# PADCFG_CTRL_PADCFG_CTRL_CFG0_04080000h register map
Vendor: Texas Instruments
Peripheral module from a debugger description file (folder am62L).
Registers are 32-bit, access per field, reset 0x8214007 unless marked. A register's access mark holds for its fields unless they carry their own. Offsets are as the file gives them; lines under a group give offsets from that group; [hi:lo] are bit positions; {n}, {i} and the like mark numbered series; 'fields as' and 'values as' point back to an identical list; <NAME> marks a mode.

## PADCFG_CTRL_CFG0 (part 1 of 2)
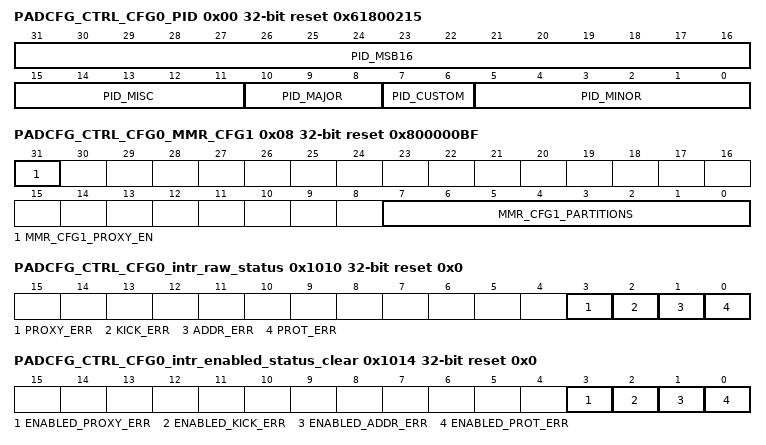
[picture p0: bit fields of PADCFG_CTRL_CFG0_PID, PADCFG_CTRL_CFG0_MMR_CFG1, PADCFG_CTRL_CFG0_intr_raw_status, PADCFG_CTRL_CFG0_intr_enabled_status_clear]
0x00 PADCFG_CTRL_CFG0_PID ro reset 0x61800215
  [31:16] PID_MSB16 — Reset Source: mod_g_rst_n
  [15:11] PID_MISC — Reset Source: mod_g_rst_n
  [10:8] PID_MAJOR — Reset Source: mod_g_rst_n
  [7:6] PID_CUSTOM — Reset Source: mod_g_rst_n
  [5:0] PID_MINOR — Reset Source: mod_g_rst_n
0x08 PADCFG_CTRL_CFG0_MMR_CFG1 ro reset 0x800000BF — Indicates the MMR configuration
  [31] MMR_CFG1_PROXY_EN — Proxy addressing enabled Reset Source: mod_por_rst_n
  [7:0] MMR_CFG1_PARTITIONS — Indicates present partitions Reset Source: mod_por_rst_n
0x1010 PADCFG_CTRL_CFG0_intr_raw_status access not given reset 0x0
  [3] PROXY_ERR — Proxy0 access violation error. Raw status is read. Write a 1 to set the status. Writing a 0 has no effect. Reset Source: mod_g_rst_n (access R/W1TS)
  [2] KICK_ERR — Kick access violation error. Raw status is read. Write a 1 to set the status. Writing a 0 has no effect. Reset Source: mod_g_rst_n (access R/W1TS)
  [1] ADDR_ERR — Addressing violation error. Raw status is read. Write a 1 to set the status. Writing a 0 has no effect. Reset Source: mod_g_rst_n (access R/W1TS)
  [0] PROT_ERR — Protection violation error. Raw status is read. Write a 1 to set the status. Writing a 0 has no effect. Reset Source: mod_g_rst_n (access R/W1TS)
0x1014 PADCFG_CTRL_CFG0_intr_enabled_status_clear access not given reset 0x0
  [3] ENABLED_PROXY_ERR — Proxy0 access violation error. Enabled status is read. Write a 1 to clear the status. Writing a 0 has no effect. Reset Source: mod_g_rst_n (access R/W1TC)
  [2] ENABLED_KICK_ERR — Kick access violation error. Enabled status is read. Write a 1 to clear the status. Writing a 0 has no effect. Reset Source: mod_g_rst_n (access R/W1TC)
  [1] ENABLED_ADDR_ERR — Addressing violation error. Enabled status is read. Write a 1 to clear the status. Writing a 0 has no effect. Reset Source: mod_g_rst_n (access R/W1TC)
  [0] ENABLED_PROT_ERR — Protection violation error. Enabled status is read. Write a 1 to clear the status. Writing a 0 has no effect. Reset Source: mod_g_rst_n (access R/W1TC)
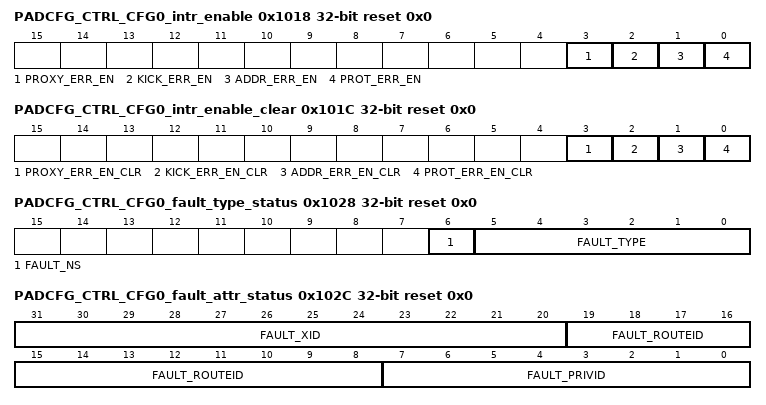
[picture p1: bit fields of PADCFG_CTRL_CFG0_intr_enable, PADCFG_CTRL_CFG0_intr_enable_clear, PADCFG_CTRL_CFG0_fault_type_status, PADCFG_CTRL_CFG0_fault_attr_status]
0x1018 PADCFG_CTRL_CFG0_intr_enable access not given reset 0x0
  [3] PROXY_ERR_EN — Proxy0 access violation error enable. Write a 1 to set the enable. Writing a 0 has no effect. Reset Source: mod_g_rst_n (access R/W1TS)
  [2] KICK_ERR_EN — Kick access violation error enable. Write a 1 to set the enable. Writing a 0 has no effect. Reset Source: mod_g_rst_n (access R/W1TS)
  [1] ADDR_ERR_EN — Addressing violation error enable. Write a 1 to set the enable. Writing a 0 has no effect. Reset Source: mod_g_rst_n (access R/W1TS)
  [0] PROT_ERR_EN — Protection violation error enable. Write a 1 to set the enable. Writing a 0 has no effect. Reset Source: mod_g_rst_n (access R/W1TS)
0x101C PADCFG_CTRL_CFG0_intr_enable_clear access not given reset 0x0
  [3] PROXY_ERR_EN_CLR — Proxy0 access violation error enable clear. Write a 1 to clear the enable. Writing a 0 has no effect. Reset Source: mod_g_rst_n (access R/W1TC)
  [2] KICK_ERR_EN_CLR — Kick access violation error enable clear. Write a 1 to clear the enable. Writing a 0 has no effect. Reset Source: mod_g_rst_n (access R/W1TC)
  [1] ADDR_ERR_EN_CLR — Addressing violation error enable clear. Write a 1 to clear the enable. Writing a 0 has no effect. Reset Source: mod_g_rst_n (access R/W1TC)
  [0] PROT_ERR_EN_CLR — Protection violation error enable clear. Write a 1 to clear the enable. Writing a 0 has no effect. Reset Source: mod_g_rst_n (access R/W1TC)
0x1020 PADCFG_CTRL_CFG0_eoi rw reset 0x0
  [7:0] EOI_VECTOR — EOI vector value. Write this with interrupt distribution value in the chip. Reset Source: mod_g_rst_n
0x1024 PADCFG_CTRL_CFG0_fault_address ro reset 0x0
  [31:0] FAULT_ADDR — Fault Address. Reset Source: mod_g_rst_n
0x1028 PADCFG_CTRL_CFG0_fault_type_status ro reset 0x0
  [6] FAULT_NS — Non-secure access. Reset Source: mod_g_rst_n
  [5:0] FAULT_TYPE — Fault Type 10_0000 = Supervisor read fault - priv = 1 dir = 1 dtype != 1 01_0000 = Supervisor write fault - priv = 1 dir = 0 00_1000 = Supervisor execute fault - priv = 1 dir = 1 dtype = 1 00_0100 = User read fault - priv = 0 dir = 1 dtype = 1 00_0010 = User write fault - priv = 0 dir = 0 00_0001 = User execute fault - priv = 0 dir = 1 dtype = 1 00_0000 = No fault Reset Source: mod_g_rst_n
0x102C PADCFG_CTRL_CFG0_fault_attr_status ro reset 0x0
  [31:20] FAULT_XID — XID. Reset Source: mod_g_rst_n
  [19:8] FAULT_ROUTEID — Route ID. Reset Source: mod_g_rst_n
  [7:0] FAULT_PRIVID — Privilege ID. Reset Source: mod_g_rst_n
0x1030 PADCFG_CTRL_CFG0_fault_clear wo reset 0x0
  [0] FAULT_CLR — Fault clear. Writing a 1 clears the current fault. Writing a 0 has no effect. Reset Source: mod_g_rst_n
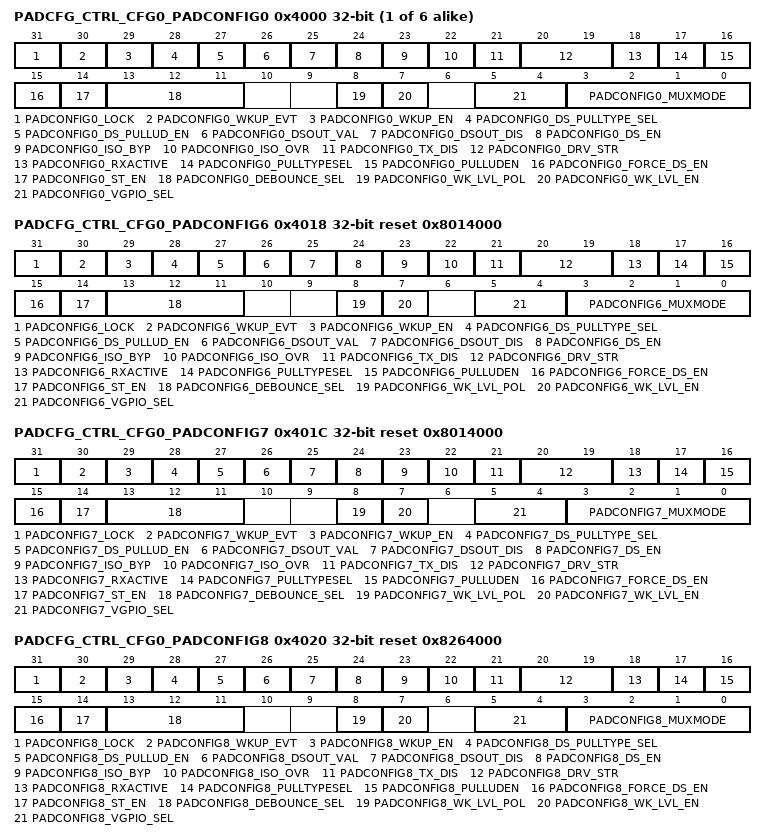
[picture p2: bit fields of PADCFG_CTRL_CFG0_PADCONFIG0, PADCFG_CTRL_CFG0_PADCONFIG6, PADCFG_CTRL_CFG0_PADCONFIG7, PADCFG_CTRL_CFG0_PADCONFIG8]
{0x4000+4i} PADCFG_CTRL_CFG0_PADCONFIG{i} (i=0..5) — Register to control pin configuration and muxing
  [31] PADCONFIG{i}_LOCK rw — Lock 0 - Padconfig register is unlocked 1 - Padconfig register is locked from further writes Reset Source: mod_por_rst_n
  [30] PADCONFIG{i}_WKUP_EVT ro — Wakeup event status 0 - No wake event on pin 1 - Wake event occurred on pin Reset Source: mod_por_rst_n
  [29] PADCONFIG{i}_WKUP_EN rw — Wakeup enable 0 - Wakeup operation disabled 1 - Wakeup operation enabled Reset Source: mod_por_rst_n
  [28] PADCONFIG{i}_DS_PULLTYPE_SEL rw — Deep Sleep pull-up/down selection 0 - Offmode pulldown selected 1 - Offmode pullup selected Reset Source: mod_por_rst_n
  [27] PADCONFIG{i}_DS_PULLUD_EN rw — Deep Sleep pull-up/down enable (active low) 0 - Pullup / pulldown is enabled 1 - Pullup / pulldown is disabled Reset Source: mod_por_rst_n
  [26] PADCONFIG{i}_DSOUT_VAL rw — Deep Sleep output value 0 - Output value is 0 1 - Output value is 1 Reset Source: mod_por_rst_n
  [25] PADCONFIG{i}_DSOUT_DIS rw — Deep Sleep output disable 0 - Output enabled 1 - Output disabled Reset Source: mod_por_rst_n
  [24] PADCONFIG{i}_DS_EN rw — Deep Sleep override control 0 - IO keeps its previous state when Deep Sleep mode is active 1 - IO state is forced to OFF mode value when Deep Sleep mode is active Reset Source: mod_por_rst_n
  [23] PADCONFIG{i}_ISO_BYP rw — Isolation Bypass0 - IO isolation is preserved1 - IO isolation is bypassed Reset Source: mod_por_rst_n
  [22] PADCONFIG{i}_ISO_OVR rw — Isolation Override0 - IO isolation is preserved1 - IO isolation is overridden Reset Source: mod_por_rst_n
  [21] PADCONFIG{i}_TX_DIS rw — Driver Disable0 - Driver is enabled1 - Driver is disabled Reset Source: mod_por_rst_n
  [20:19] PADCONFIG{i}_DRV_STR rw — Drive Strength Control for dual volatge IOs. Selects the drive strength value for LVCMOS pins. For 1.8V only IO, bitundefined maps to Slew Control pin. Reset Source: mod_por_rst_n
  [18] PADCONFIG{i}_RXACTIVE rw — Input enable for the Pad0 - Receiver disabled1 - Receiver enabled Reset Source: mod_por_rst_n
  [17] PADCONFIG{i}_PULLTYPESEL rw — Pad Pullup / Pulldown type selection0 - Pulldown selected1 - Pullup selected Reset Source: mod_por_rst_n
  [16] PADCONFIG{i}_PULLUDEN rw — Pad Pullup / Pulldown enable. This is an active low signal.0 - Pullup / Pulldown enabled1 - Pullup / Pulldown disabled Reset Source: mod_por_rst_n
  [15] PADCONFIG{i}_FORCE_DS_EN rw — Enable pad Deep Sleep controls by overriding WKUP DM gating0 - Deep Sleep pad controls are gated by the WKUP DM1 - Activate Deep Sleep pad controls (override WKUP DM gating logic) Reset Source: mod_por_rst_n
  [14] PADCONFIG{i}_ST_EN rw — Receiver Schmitt Trigger enable 0 - Schmitt trigger input disabled 1 - Schmitt trigger input enabled Reset Source: mod_por_rst_n
  [13:11] PADCONFIG{i}_DEBOUNCE_SEL rw — Selects the debouce period for the pad. Reset Source: mod_por_rst_n
  [8] PADCONFIG{i}_WK_LVL_POL rw — Level Sensitive Wakeup PolarityThis bit is not relevant unless wk_lvl_en is set to 1'b1.0 - Low. A low (0) value on the pin causes a wakeup1 - High. A high (1) value on the pin causes a wakeup Reset Source: mod_por_rst_n
  [7] PADCONFIG{i}_WK_LVL_EN rw — Level Sensitive Wakeup Enable0 - Disabled. Wakeup is triggered by change of the pin input value1 - Enabled. Wakeup is triggered when the pin matches the value specified by wk_lvl_pol. The chosen polarity must be maintained. (e.g. until wakeup completion is confirmed) Reset Source: mod_por_rst_n
  [5:4] PADCONFIG{i}_VGPIO_SEL rw — Virtual MAIN_GPIO instance select.These bits select which instance of GPIO is used for this I/O pad. This allows protection between two different Processor virtual worlds. These bits have no effect if GPIO mode (muxmode=7) is not selected for the PAD. Refer Pinmux to identify if a pin supports virtual GPIO function or not.Field values (others are reserved):2'b00 - Implement GPIO in GPIO_0 instance2'b01 - Implement GPIO in GPIO_2 instance Reset Source: mod_por_rst_n
  [3:0] PADCONFIG{i}_MUXMODE rw — Pad functional signal mux selectionField values (others are reserved):4'b0000 - Mux Mode 04'b0001 - Mux Mode 14'b0010 - Mux Mode 24'b0011 - Mux Mode 34'b0100 - Mux Mode 44'b0101 - Mux Mode 54'b0110 - Mux Mode 64'b0111 - Mux Mode 74'b1000 - Mux Mode 84'b1001 - Mux Mode 94'b1010 - Mux Mode 104'b1011 - Mux Mode 114'b1100 - Mux Mode 124'b1101 - Mux Mode 134'b1110 - Mux Mode 144'b1111 - Mux Mode 15 Reset Source: mod_por_rst_n
0x4018 PADCFG_CTRL_CFG0_PADCONFIG6 reset 0x8014000 — Register to control pin configuration and muxing
  [31] PADCONFIG6_LOCK rw — Lock 0 - Padconfig register is unlocked 1 - Padconfig register is locked from further writes Reset Source: mod_por_rst_n
  [30] PADCONFIG6_WKUP_EVT ro — Wakeup event status 0 - No wake event on pin 1 - Wake event occurred on pin Reset Source: mod_por_rst_n
  [29] PADCONFIG6_WKUP_EN rw — Wakeup enable 0 - Wakeup operation disabled 1 - Wakeup operation enabled Reset Source: mod_por_rst_n
  [28] PADCONFIG6_DS_PULLTYPE_SEL rw — Deep Sleep pull-up/down selection 0 - Offmode pulldown selected 1 - Offmode pullup selected Reset Source: mod_por_rst_n
  [27] PADCONFIG6_DS_PULLUD_EN rw — Deep Sleep pull-up/down enable (active low) 0 - Pullup / pulldown is enabled 1 - Pullup / pulldown is disabled Reset Source: mod_por_rst_n
  [26] PADCONFIG6_DSOUT_VAL rw — Deep Sleep output value 0 - Output value is 0 1 - Output value is 1 Reset Source: mod_por_rst_n
  [25] PADCONFIG6_DSOUT_DIS rw — Deep Sleep output disable 0 - Output enabled 1 - Output disabled Reset Source: mod_por_rst_n
  [24] PADCONFIG6_DS_EN rw — Deep Sleep override control 0 - IO keeps its previous state when Deep Sleep mode is active 1 - IO state is forced to OFF mode value when Deep Sleep mode is active Reset Source: mod_por_rst_n
  [23] PADCONFIG6_ISO_BYP rw — Isolation Bypass0 - IO isolation is preserved1 - IO isolation is bypassed Reset Source: mod_por_rst_n
  [22] PADCONFIG6_ISO_OVR rw — Isolation Override0 - IO isolation is preserved1 - IO isolation is overridden Reset Source: mod_por_rst_n
  [21] PADCONFIG6_TX_DIS rw — Driver Disable0 - Driver is enabled1 - Driver is disabled Reset Source: mod_por_rst_n
  [20:19] PADCONFIG6_DRV_STR rw — Drive Strength Control for dual volatge IOs. Selects the drive strength value for LVCMOS pins. For 1.8V only IO, bitundefined maps to Slew Control pin. Reset Source: mod_por_rst_n
  [18] PADCONFIG6_RXACTIVE rw — Input enable for the Pad0 - Receiver disabled1 - Receiver enabled Reset Source: mod_por_rst_n
  [17] PADCONFIG6_PULLTYPESEL rw — Pad Pullup / Pulldown type selection0 - Pulldown selected1 - Pullup selected Reset Source: mod_por_rst_n
  [16] PADCONFIG6_PULLUDEN rw — Pad Pullup / Pulldown enable. This is an active low signal.0 - Pullup / Pulldown enabled1 - Pullup / Pulldown disabled Reset Source: mod_por_rst_n
  [15] PADCONFIG6_FORCE_DS_EN rw — Enable pad Deep Sleep controls by overriding WKUP DM gating0 - Deep Sleep pad controls are gated by the WKUP DM1 - Activate Deep Sleep pad controls (override WKUP DM gating logic) Reset Source: mod_por_rst_n
  [14] PADCONFIG6_ST_EN rw — Receiver Schmitt Trigger enable 0 - Schmitt trigger input disabled 1 - Schmitt trigger input enabled Reset Source: mod_por_rst_n
  [13:11] PADCONFIG6_DEBOUNCE_SEL rw — Selects the debouce period for the pad. Reset Source: mod_por_rst_n
  [8] PADCONFIG6_WK_LVL_POL rw — Level Sensitive Wakeup PolarityThis bit is not relevant unless wk_lvl_en is set to 1'b1.0 - Low. A low (0) value on the pin causes a wakeup1 - High. A high (1) value on the pin causes a wakeup Reset Source: mod_por_rst_n
  [7] PADCONFIG6_WK_LVL_EN rw — Level Sensitive Wakeup Enable0 - Disabled. Wakeup is triggered by change of the pin input value1 - Enabled. Wakeup is triggered when the pin matches the value specified by wk_lvl_pol. The chosen polarity must be maintained. (e.g. until wakeup completion is confirmed) Reset Source: mod_por_rst_n
  [5:4] PADCONFIG6_VGPIO_SEL rw — Virtual MAIN_GPIO instance select.These bits select which instance of GPIO is used for this I/O pad. This allows protection between two different Processor virtual worlds. These bits have no effect if GPIO mode (muxmode=7) is not selected for the PAD. Refer Pinmux to identify if a pin supports virtual GPIO function or not.Field values (others are reserved):2'b00 - Implement GPIO in GPIO_0 instance2'b01 - Implement GPIO in GPIO_2 instance Reset Source: mod_por_rst_n
  [3:0] PADCONFIG6_MUXMODE rw — Pad functional signal mux selectionField values (others are reserved):4'b0000 - Mux Mode 04'b0001 - Mux Mode 14'b0010 - Mux Mode 24'b0011 - Mux Mode 34'b0100 - Mux Mode 44'b0101 - Mux Mode 54'b0110 - Mux Mode 64'b0111 - Mux Mode 74'b1000 - Mux Mode 84'b1001 - Mux Mode 94'b1010 - Mux Mode 104'b1011 - Mux Mode 114'b1100 - Mux Mode 124'b1101 - Mux Mode 134'b1110 - Mux Mode 144'b1111 - Mux Mode 15 Reset Source: mod_por_rst_n
0x401C PADCFG_CTRL_CFG0_PADCONFIG7 reset 0x8014000 — Register to control pin configuration and muxing
  [31] PADCONFIG7_LOCK rw — Lock 0 - Padconfig register is unlocked 1 - Padconfig register is locked from further writes Reset Source: mod_por_rst_n
  [30] PADCONFIG7_WKUP_EVT ro — Wakeup event status 0 - No wake event on pin 1 - Wake event occurred on pin Reset Source: mod_por_rst_n
  [29] PADCONFIG7_WKUP_EN rw — Wakeup enable 0 - Wakeup operation disabled 1 - Wakeup operation enabled Reset Source: mod_por_rst_n
  [28] PADCONFIG7_DS_PULLTYPE_SEL rw — Deep Sleep pull-up/down selection 0 - Offmode pulldown selected 1 - Offmode pullup selected Reset Source: mod_por_rst_n
  [27] PADCONFIG7_DS_PULLUD_EN rw — Deep Sleep pull-up/down enable (active low) 0 - Pullup / pulldown is enabled 1 - Pullup / pulldown is disabled Reset Source: mod_por_rst_n
  [26] PADCONFIG7_DSOUT_VAL rw — Deep Sleep output value 0 - Output value is 0 1 - Output value is 1 Reset Source: mod_por_rst_n
  [25] PADCONFIG7_DSOUT_DIS rw — Deep Sleep output disable 0 - Output enabled 1 - Output disabled Reset Source: mod_por_rst_n
  [24] PADCONFIG7_DS_EN rw — Deep Sleep override control 0 - IO keeps its previous state when Deep Sleep mode is active 1 - IO state is forced to OFF mode value when Deep Sleep mode is active Reset Source: mod_por_rst_n
  [23] PADCONFIG7_ISO_BYP rw — Isolation Bypass0 - IO isolation is preserved1 - IO isolation is bypassed Reset Source: mod_por_rst_n
  [22] PADCONFIG7_ISO_OVR rw — Isolation Override0 - IO isolation is preserved1 - IO isolation is overridden Reset Source: mod_por_rst_n
  [21] PADCONFIG7_TX_DIS rw — Driver Disable0 - Driver is enabled1 - Driver is disabled Reset Source: mod_por_rst_n
  [20:19] PADCONFIG7_DRV_STR rw — Drive Strength Control for dual volatge IOs. Selects the drive strength value for LVCMOS pins. For 1.8V only IO, bitundefined maps to Slew Control pin. Reset Source: mod_por_rst_n
  [18] PADCONFIG7_RXACTIVE rw — Input enable for the Pad0 - Receiver disabled1 - Receiver enabled Reset Source: mod_por_rst_n
  [17] PADCONFIG7_PULLTYPESEL rw — Pad Pullup / Pulldown type selection0 - Pulldown selected1 - Pullup selected Reset Source: mod_por_rst_n
  [16] PADCONFIG7_PULLUDEN rw — Pad Pullup / Pulldown enable. This is an active low signal.0 - Pullup / Pulldown enabled1 - Pullup / Pulldown disabled Reset Source: mod_por_rst_n
  [15] PADCONFIG7_FORCE_DS_EN rw — Enable pad Deep Sleep controls by overriding WKUP DM gating0 - Deep Sleep pad controls are gated by the WKUP DM1 - Activate Deep Sleep pad controls (override WKUP DM gating logic) Reset Source: mod_por_rst_n
  [14] PADCONFIG7_ST_EN rw — Receiver Schmitt Trigger enable 0 - Schmitt trigger input disabled 1 - Schmitt trigger input enabled Reset Source: mod_por_rst_n
  [13:11] PADCONFIG7_DEBOUNCE_SEL rw — Selects the debouce period for the pad. Reset Source: mod_por_rst_n
  [8] PADCONFIG7_WK_LVL_POL rw — Level Sensitive Wakeup PolarityThis bit is not relevant unless wk_lvl_en is set to 1'b1.0 - Low. A low (0) value on the pin causes a wakeup1 - High. A high (1) value on the pin causes a wakeup Reset Source: mod_por_rst_n
  [7] PADCONFIG7_WK_LVL_EN rw — Level Sensitive Wakeup Enable0 - Disabled. Wakeup is triggered by change of the pin input value1 - Enabled. Wakeup is triggered when the pin matches the value specified by wk_lvl_pol. The chosen polarity must be maintained. (e.g. until wakeup completion is confirmed) Reset Source: mod_por_rst_n
  [5:4] PADCONFIG7_VGPIO_SEL rw — Virtual MAIN_GPIO instance select.These bits select which instance of GPIO is used for this I/O pad. This allows protection between two different Processor virtual worlds. These bits have no effect if GPIO mode (muxmode=7) is not selected for the PAD. Refer Pinmux to identify if a pin supports virtual GPIO function or not.Field values (others are reserved):2'b00 - Implement GPIO in GPIO_0 instance2'b01 - Implement GPIO in GPIO_2 instance Reset Source: mod_por_rst_n
  [3:0] PADCONFIG7_MUXMODE rw — Pad functional signal mux selectionField values (others are reserved):4'b0000 - Mux Mode 04'b0001 - Mux Mode 14'b0010 - Mux Mode 24'b0011 - Mux Mode 34'b0100 - Mux Mode 44'b0101 - Mux Mode 54'b0110 - Mux Mode 64'b0111 - Mux Mode 74'b1000 - Mux Mode 84'b1001 - Mux Mode 94'b1010 - Mux Mode 104'b1011 - Mux Mode 114'b1100 - Mux Mode 124'b1101 - Mux Mode 134'b1110 - Mux Mode 144'b1111 - Mux Mode 15 Reset Source: mod_por_rst_n
0x4020 PADCFG_CTRL_CFG0_PADCONFIG8 reset 0x8264000 — Register to control pin configuration and muxing
  [31] PADCONFIG8_LOCK rw — Lock 0 - Padconfig register is unlocked 1 - Padconfig register is locked from further writes Reset Source: mod_por_rst_n
  [30] PADCONFIG8_WKUP_EVT ro — Wakeup event status 0 - No wake event on pin 1 - Wake event occurred on pin Reset Source: mod_por_rst_n
  [29] PADCONFIG8_WKUP_EN rw — Wakeup enable 0 - Wakeup operation disabled 1 - Wakeup operation enabled Reset Source: mod_por_rst_n
  [28] PADCONFIG8_DS_PULLTYPE_SEL rw — Deep Sleep pull-up/down selection 0 - Offmode pulldown selected 1 - Offmode pullup selected Reset Source: mod_por_rst_n
  [27] PADCONFIG8_DS_PULLUD_EN rw — Deep Sleep pull-up/down enable (active low) 0 - Pullup / pulldown is enabled 1 - Pullup / pulldown is disabled Reset Source: mod_por_rst_n
  [26] PADCONFIG8_DSOUT_VAL rw — Deep Sleep output value 0 - Output value is 0 1 - Output value is 1 Reset Source: mod_por_rst_n
  [25] PADCONFIG8_DSOUT_DIS rw — Deep Sleep output disable 0 - Output enabled 1 - Output disabled Reset Source: mod_por_rst_n
  [24] PADCONFIG8_DS_EN rw — Deep Sleep override control 0 - IO keeps its previous state when Deep Sleep mode is active 1 - IO state is forced to OFF mode value when Deep Sleep mode is active Reset Source: mod_por_rst_n
  [23] PADCONFIG8_ISO_BYP rw — Isolation Bypass0 - IO isolation is preserved1 - IO isolation is bypassed Reset Source: mod_por_rst_n
  [22] PADCONFIG8_ISO_OVR rw — Isolation Override0 - IO isolation is preserved1 - IO isolation is overridden Reset Source: mod_por_rst_n
  [21] PADCONFIG8_TX_DIS rw — Driver Disable0 - Driver is enabled1 - Driver is disabled Reset Source: mod_por_rst_n
  [20:19] PADCONFIG8_DRV_STR rw — Drive Strength Control for dual volatge IOs. Selects the drive strength value for LVCMOS pins. For 1.8V only IO, bitundefined maps to Slew Control pin. Reset Source: mod_por_rst_n
  [18] PADCONFIG8_RXACTIVE rw — Input enable for the Pad0 - Receiver disabled1 - Receiver enabled Reset Source: mod_por_rst_n
  [17] PADCONFIG8_PULLTYPESEL rw — Pad Pullup / Pulldown type selection0 - Pulldown selected1 - Pullup selected Reset Source: mod_por_rst_n
  [16] PADCONFIG8_PULLUDEN rw — Pad Pullup / Pulldown enable. This is an active low signal.0 - Pullup / Pulldown enabled1 - Pullup / Pulldown disabled Reset Source: mod_por_rst_n
  [15] PADCONFIG8_FORCE_DS_EN rw — Enable pad Deep Sleep controls by overriding WKUP DM gating0 - Deep Sleep pad controls are gated by the WKUP DM1 - Activate Deep Sleep pad controls (override WKUP DM gating logic) Reset Source: mod_por_rst_n
  [14] PADCONFIG8_ST_EN rw — Receiver Schmitt Trigger enable 0 - Schmitt trigger input disabled 1 - Schmitt trigger input enabled Reset Source: mod_por_rst_n
  [13:11] PADCONFIG8_DEBOUNCE_SEL rw — Selects the debouce period for the pad. Reset Source: mod_por_rst_n
  [8] PADCONFIG8_WK_LVL_POL rw — Level Sensitive Wakeup PolarityThis bit is not relevant unless wk_lvl_en is set to 1'b1.0 - Low. A low (0) value on the pin causes a wakeup1 - High. A high (1) value on the pin causes a wakeup Reset Source: mod_por_rst_n
  [7] PADCONFIG8_WK_LVL_EN rw — Level Sensitive Wakeup Enable0 - Disabled. Wakeup is triggered by change of the pin input value1 - Enabled. Wakeup is triggered when the pin matches the value specified by wk_lvl_pol. The chosen polarity must be maintained. (e.g. until wakeup completion is confirmed) Reset Source: mod_por_rst_n
  [5:4] PADCONFIG8_VGPIO_SEL rw — Virtual MAIN_GPIO instance select.These bits select which instance of GPIO is used for this I/O pad. This allows protection between two different Processor virtual worlds. These bits have no effect if GPIO mode (muxmode=7) is not selected for the PAD. Refer Pinmux to identify if a pin supports virtual GPIO function or not.Field values (others are reserved):2'b00 - Implement GPIO in GPIO_0 instance2'b01 - Implement GPIO in GPIO_2 instance Reset Source: mod_por_rst_n
  [3:0] PADCONFIG8_MUXMODE rw — Pad functional signal mux selectionField values (others are reserved):4'b0000 - Mux Mode 04'b0001 - Mux Mode 14'b0010 - Mux Mode 24'b0011 - Mux Mode 34'b0100 - Mux Mode 44'b0101 - Mux Mode 54'b0110 - Mux Mode 64'b0111 - Mux Mode 74'b1000 - Mux Mode 84'b1001 - Mux Mode 94'b1010 - Mux Mode 104'b1011 - Mux Mode 114'b1100 - Mux Mode 124'b1101 - Mux Mode 134'b1110 - Mux Mode 144'b1111 - Mux Mode 15 Reset Source: mod_por_rst_n
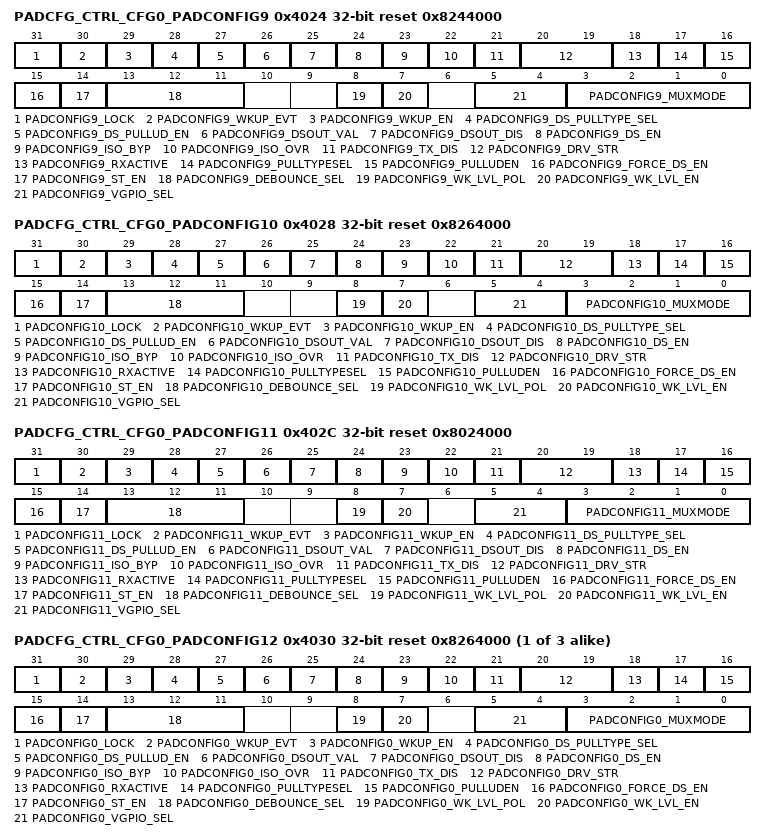
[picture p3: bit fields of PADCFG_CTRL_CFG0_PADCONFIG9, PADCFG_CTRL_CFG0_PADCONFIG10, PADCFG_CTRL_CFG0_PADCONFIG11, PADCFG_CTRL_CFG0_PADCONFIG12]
0x4024 PADCFG_CTRL_CFG0_PADCONFIG9 reset 0x8244000 — Register to control pin configuration and muxing
  [31] PADCONFIG9_LOCK rw — Lock 0 - Padconfig register is unlocked 1 - Padconfig register is locked from further writes Reset Source: mod_por_rst_n
  [30] PADCONFIG9_WKUP_EVT ro — Wakeup event status 0 - No wake event on pin 1 - Wake event occurred on pin Reset Source: mod_por_rst_n
  [29] PADCONFIG9_WKUP_EN rw — Wakeup enable 0 - Wakeup operation disabled 1 - Wakeup operation enabled Reset Source: mod_por_rst_n
  [28] PADCONFIG9_DS_PULLTYPE_SEL rw — Deep Sleep pull-up/down selection 0 - Offmode pulldown selected 1 - Offmode pullup selected Reset Source: mod_por_rst_n
  [27] PADCONFIG9_DS_PULLUD_EN rw — Deep Sleep pull-up/down enable (active low) 0 - Pullup / pulldown is enabled 1 - Pullup / pulldown is disabled Reset Source: mod_por_rst_n
  [26] PADCONFIG9_DSOUT_VAL rw — Deep Sleep output value 0 - Output value is 0 1 - Output value is 1 Reset Source: mod_por_rst_n
  [25] PADCONFIG9_DSOUT_DIS rw — Deep Sleep output disable 0 - Output enabled 1 - Output disabled Reset Source: mod_por_rst_n
  [24] PADCONFIG9_DS_EN rw — Deep Sleep override control 0 - IO keeps its previous state when Deep Sleep mode is active 1 - IO state is forced to OFF mode value when Deep Sleep mode is active Reset Source: mod_por_rst_n
  [23] PADCONFIG9_ISO_BYP rw — Isolation Bypass0 - IO isolation is preserved1 - IO isolation is bypassed Reset Source: mod_por_rst_n
  [22] PADCONFIG9_ISO_OVR rw — Isolation Override0 - IO isolation is preserved1 - IO isolation is overridden Reset Source: mod_por_rst_n
  [21] PADCONFIG9_TX_DIS rw — Driver Disable0 - Driver is enabled1 - Driver is disabled Reset Source: mod_por_rst_n
  [20:19] PADCONFIG9_DRV_STR rw — Drive Strength Control for dual volatge IOs. Selects the drive strength value for LVCMOS pins. For 1.8V only IO, bitundefined maps to Slew Control pin. Reset Source: mod_por_rst_n
  [18] PADCONFIG9_RXACTIVE rw — Input enable for the Pad0 - Receiver disabled1 - Receiver enabled Reset Source: mod_por_rst_n
  [17] PADCONFIG9_PULLTYPESEL rw — Pad Pullup / Pulldown type selection0 - Pulldown selected1 - Pullup selected Reset Source: mod_por_rst_n
  [16] PADCONFIG9_PULLUDEN rw — Pad Pullup / Pulldown enable. This is an active low signal.0 - Pullup / Pulldown enabled1 - Pullup / Pulldown disabled Reset Source: mod_por_rst_n
  [15] PADCONFIG9_FORCE_DS_EN rw — Enable pad Deep Sleep controls by overriding WKUP DM gating0 - Deep Sleep pad controls are gated by the WKUP DM1 - Activate Deep Sleep pad controls (override WKUP DM gating logic) Reset Source: mod_por_rst_n
  [14] PADCONFIG9_ST_EN rw — Receiver Schmitt Trigger enable 0 - Schmitt trigger input disabled 1 - Schmitt trigger input enabled Reset Source: mod_por_rst_n
  [13:11] PADCONFIG9_DEBOUNCE_SEL rw — Selects the debouce period for the pad. Reset Source: mod_por_rst_n
  [8] PADCONFIG9_WK_LVL_POL rw — Level Sensitive Wakeup PolarityThis bit is not relevant unless wk_lvl_en is set to 1'b1.0 - Low. A low (0) value on the pin causes a wakeup1 - High. A high (1) value on the pin causes a wakeup Reset Source: mod_por_rst_n
  [7] PADCONFIG9_WK_LVL_EN rw — Level Sensitive Wakeup Enable0 - Disabled. Wakeup is triggered by change of the pin input value1 - Enabled. Wakeup is triggered when the pin matches the value specified by wk_lvl_pol. The chosen polarity must be maintained. (e.g. until wakeup completion is confirmed) Reset Source: mod_por_rst_n
  [5:4] PADCONFIG9_VGPIO_SEL rw — Virtual MAIN_GPIO instance select.These bits select which instance of GPIO is used for this I/O pad. This allows protection between two different Processor virtual worlds. These bits have no effect if GPIO mode (muxmode=7) is not selected for the PAD. Refer Pinmux to identify if a pin supports virtual GPIO function or not.Field values (others are reserved):2'b00 - Implement GPIO in GPIO_0 instance2'b01 - Implement GPIO in GPIO_2 instance Reset Source: mod_por_rst_n
  [3:0] PADCONFIG9_MUXMODE rw — Pad functional signal mux selectionField values (others are reserved):4'b0000 - Mux Mode 04'b0001 - Mux Mode 14'b0010 - Mux Mode 24'b0011 - Mux Mode 34'b0100 - Mux Mode 44'b0101 - Mux Mode 54'b0110 - Mux Mode 64'b0111 - Mux Mode 74'b1000 - Mux Mode 84'b1001 - Mux Mode 94'b1010 - Mux Mode 104'b1011 - Mux Mode 114'b1100 - Mux Mode 124'b1101 - Mux Mode 134'b1110 - Mux Mode 144'b1111 - Mux Mode 15 Reset Source: mod_por_rst_n
0x4028 PADCFG_CTRL_CFG0_PADCONFIG10 reset 0x8264000 — Register to control pin configuration and muxing
  [31] PADCONFIG10_LOCK rw — Lock 0 - Padconfig register is unlocked 1 - Padconfig register is locked from further writes Reset Source: mod_por_rst_n
  [30] PADCONFIG10_WKUP_EVT ro — Wakeup event status 0 - No wake event on pin 1 - Wake event occurred on pin Reset Source: mod_por_rst_n
  [29] PADCONFIG10_WKUP_EN rw — Wakeup enable 0 - Wakeup operation disabled 1 - Wakeup operation enabled Reset Source: mod_por_rst_n
  [28] PADCONFIG10_DS_PULLTYPE_SEL rw — Deep Sleep pull-up/down selection 0 - Offmode pulldown selected 1 - Offmode pullup selected Reset Source: mod_por_rst_n
  [27] PADCONFIG10_DS_PULLUD_EN rw — Deep Sleep pull-up/down enable (active low) 0 - Pullup / pulldown is enabled 1 - Pullup / pulldown is disabled Reset Source: mod_por_rst_n
  [26] PADCONFIG10_DSOUT_VAL rw — Deep Sleep output value 0 - Output value is 0 1 - Output value is 1 Reset Source: mod_por_rst_n
  [25] PADCONFIG10_DSOUT_DIS rw — Deep Sleep output disable 0 - Output enabled 1 - Output disabled Reset Source: mod_por_rst_n
  [24] PADCONFIG10_DS_EN rw — Deep Sleep override control 0 - IO keeps its previous state when Deep Sleep mode is active 1 - IO state is forced to OFF mode value when Deep Sleep mode is active Reset Source: mod_por_rst_n
  [23] PADCONFIG10_ISO_BYP rw — Isolation Bypass0 - IO isolation is preserved1 - IO isolation is bypassed Reset Source: mod_por_rst_n
  [22] PADCONFIG10_ISO_OVR rw — Isolation Override0 - IO isolation is preserved1 - IO isolation is overridden Reset Source: mod_por_rst_n
  [21] PADCONFIG10_TX_DIS rw — Driver Disable0 - Driver is enabled1 - Driver is disabled Reset Source: mod_por_rst_n
  [20:19] PADCONFIG10_DRV_STR rw — Drive Strength Control for dual volatge IOs. Selects the drive strength value for LVCMOS pins. For 1.8V only IO, bitundefined maps to Slew Control pin. Reset Source: mod_por_rst_n
  [18] PADCONFIG10_RXACTIVE rw — Input enable for the Pad0 - Receiver disabled1 - Receiver enabled Reset Source: mod_por_rst_n
  [17] PADCONFIG10_PULLTYPESEL rw — Pad Pullup / Pulldown type selection0 - Pulldown selected1 - Pullup selected Reset Source: mod_por_rst_n
  [16] PADCONFIG10_PULLUDEN rw — Pad Pullup / Pulldown enable. This is an active low signal.0 - Pullup / Pulldown enabled1 - Pullup / Pulldown disabled Reset Source: mod_por_rst_n
  [15] PADCONFIG10_FORCE_DS_EN rw — Enable pad Deep Sleep controls by overriding WKUP DM gating0 - Deep Sleep pad controls are gated by the WKUP DM1 - Activate Deep Sleep pad controls (override WKUP DM gating logic) Reset Source: mod_por_rst_n
  [14] PADCONFIG10_ST_EN rw — Receiver Schmitt Trigger enable 0 - Schmitt trigger input disabled 1 - Schmitt trigger input enabled Reset Source: mod_por_rst_n
  [13:11] PADCONFIG10_DEBOUNCE_SEL rw — Selects the debouce period for the pad. Reset Source: mod_por_rst_n
  [8] PADCONFIG10_WK_LVL_POL rw — Level Sensitive Wakeup PolarityThis bit is not relevant unless wk_lvl_en is set to 1'b1.0 - Low. A low (0) value on the pin causes a wakeup1 - High. A high (1) value on the pin causes a wakeup Reset Source: mod_por_rst_n
  [7] PADCONFIG10_WK_LVL_EN rw — Level Sensitive Wakeup Enable0 - Disabled. Wakeup is triggered by change of the pin input value1 - Enabled. Wakeup is triggered when the pin matches the value specified by wk_lvl_pol. The chosen polarity must be maintained. (e.g. until wakeup completion is confirmed) Reset Source: mod_por_rst_n
  [5:4] PADCONFIG10_VGPIO_SEL rw — Virtual MAIN_GPIO instance select.These bits select which instance of GPIO is used for this I/O pad. This allows protection between two different Processor virtual worlds. These bits have no effect if GPIO mode (muxmode=7) is not selected for the PAD. Refer Pinmux to identify if a pin supports virtual GPIO function or not.Field values (others are reserved):2'b00 - Implement GPIO in GPIO_0 instance2'b01 - Implement GPIO in GPIO_2 instance Reset Source: mod_por_rst_n
  [3:0] PADCONFIG10_MUXMODE rw — Pad functional signal mux selectionField values (others are reserved):4'b0000 - Mux Mode 04'b0001 - Mux Mode 14'b0010 - Mux Mode 24'b0011 - Mux Mode 34'b0100 - Mux Mode 44'b0101 - Mux Mode 54'b0110 - Mux Mode 64'b0111 - Mux Mode 74'b1000 - Mux Mode 84'b1001 - Mux Mode 94'b1010 - Mux Mode 104'b1011 - Mux Mode 114'b1100 - Mux Mode 124'b1101 - Mux Mode 134'b1110 - Mux Mode 144'b1111 - Mux Mode 15 Reset Source: mod_por_rst_n
0x402C PADCFG_CTRL_CFG0_PADCONFIG11 reset 0x8024000 — Register to control pin configuration and muxing
  [31] PADCONFIG11_LOCK rw — Lock 0 - Padconfig register is unlocked 1 - Padconfig register is locked from further writes Reset Source: mod_por_rst_n
  [30] PADCONFIG11_WKUP_EVT ro — Wakeup event status 0 - No wake event on pin 1 - Wake event occurred on pin Reset Source: mod_por_rst_n
  [29] PADCONFIG11_WKUP_EN rw — Wakeup enable 0 - Wakeup operation disabled 1 - Wakeup operation enabled Reset Source: mod_por_rst_n
  [28] PADCONFIG11_DS_PULLTYPE_SEL rw — Deep Sleep pull-up/down selection 0 - Offmode pulldown selected 1 - Offmode pullup selected Reset Source: mod_por_rst_n
  [27] PADCONFIG11_DS_PULLUD_EN rw — Deep Sleep pull-up/down enable (active low) 0 - Pullup / pulldown is enabled 1 - Pullup / pulldown is disabled Reset Source: mod_por_rst_n
  [26] PADCONFIG11_DSOUT_VAL rw — Deep Sleep output value 0 - Output value is 0 1 - Output value is 1 Reset Source: mod_por_rst_n
  [25] PADCONFIG11_DSOUT_DIS rw — Deep Sleep output disable 0 - Output enabled 1 - Output disabled Reset Source: mod_por_rst_n
  [24] PADCONFIG11_DS_EN rw — Deep Sleep override control 0 - IO keeps its previous state when Deep Sleep mode is active 1 - IO state is forced to OFF mode value when Deep Sleep mode is active Reset Source: mod_por_rst_n
  [23] PADCONFIG11_ISO_BYP rw — Isolation Bypass0 - IO isolation is preserved1 - IO isolation is bypassed Reset Source: mod_por_rst_n
  [22] PADCONFIG11_ISO_OVR rw — Isolation Override0 - IO isolation is preserved1 - IO isolation is overridden Reset Source: mod_por_rst_n
  [21] PADCONFIG11_TX_DIS rw — Driver Disable0 - Driver is enabled1 - Driver is disabled Reset Source: mod_por_rst_n
  [20:19] PADCONFIG11_DRV_STR rw — Drive Strength Control for dual volatge IOs. Selects the drive strength value for LVCMOS pins. For 1.8V only IO, bitundefined maps to Slew Control pin. Reset Source: mod_por_rst_n
  [18] PADCONFIG11_RXACTIVE rw — Input enable for the Pad0 - Receiver disabled1 - Receiver enabled Reset Source: mod_por_rst_n
  [17] PADCONFIG11_PULLTYPESEL rw — Pad Pullup / Pulldown type selection0 - Pulldown selected1 - Pullup selected Reset Source: mod_por_rst_n
  [16] PADCONFIG11_PULLUDEN rw — Pad Pullup / Pulldown enable. This is an active low signal.0 - Pullup / Pulldown enabled1 - Pullup / Pulldown disabled Reset Source: mod_por_rst_n
  [15] PADCONFIG11_FORCE_DS_EN rw — Enable pad Deep Sleep controls by overriding WKUP DM gating0 - Deep Sleep pad controls are gated by the WKUP DM1 - Activate Deep Sleep pad controls (override WKUP DM gating logic) Reset Source: mod_por_rst_n
  [14] PADCONFIG11_ST_EN rw — Receiver Schmitt Trigger enable 0 - Schmitt trigger input disabled 1 - Schmitt trigger input enabled Reset Source: mod_por_rst_n
  [13:11] PADCONFIG11_DEBOUNCE_SEL rw — Selects the debouce period for the pad. Reset Source: mod_por_rst_n
  [8] PADCONFIG11_WK_LVL_POL rw — Level Sensitive Wakeup PolarityThis bit is not relevant unless wk_lvl_en is set to 1'b1.0 - Low. A low (0) value on the pin causes a wakeup1 - High. A high (1) value on the pin causes a wakeup Reset Source: mod_por_rst_n
  [7] PADCONFIG11_WK_LVL_EN rw — Level Sensitive Wakeup Enable0 - Disabled. Wakeup is triggered by change of the pin input value1 - Enabled. Wakeup is triggered when the pin matches the value specified by wk_lvl_pol. The chosen polarity must be maintained. (e.g. until wakeup completion is confirmed) Reset Source: mod_por_rst_n
  [5:4] PADCONFIG11_VGPIO_SEL rw — Virtual MAIN_GPIO instance select.These bits select which instance of GPIO is used for this I/O pad. This allows protection between two different Processor virtual worlds. These bits have no effect if GPIO mode (muxmode=7) is not selected for the PAD. Refer Pinmux to identify if a pin supports virtual GPIO function or not.Field values (others are reserved):2'b00 - Implement GPIO in GPIO_0 instance2'b01 - Implement GPIO in GPIO_2 instance Reset Source: mod_por_rst_n
  [3:0] PADCONFIG11_MUXMODE rw — Pad functional signal mux selectionField values (others are reserved):4'b0000 - Mux Mode 04'b0001 - Mux Mode 14'b0010 - Mux Mode 24'b0011 - Mux Mode 34'b0100 - Mux Mode 44'b0101 - Mux Mode 54'b0110 - Mux Mode 64'b0111 - Mux Mode 74'b1000 - Mux Mode 84'b1001 - Mux Mode 94'b1010 - Mux Mode 104'b1011 - Mux Mode 114'b1100 - Mux Mode 124'b1101 - Mux Mode 134'b1110 - Mux Mode 144'b1111 - Mux Mode 15 Reset Source: mod_por_rst_n
{0x4000+4i} PADCFG_CTRL_CFG0_PADCONFIG{i} reset 0x8264000 (i=12..14) — Register to control pin configuration and muxing
  fields as PADCFG_CTRL_CFG0_PADCONFIG0
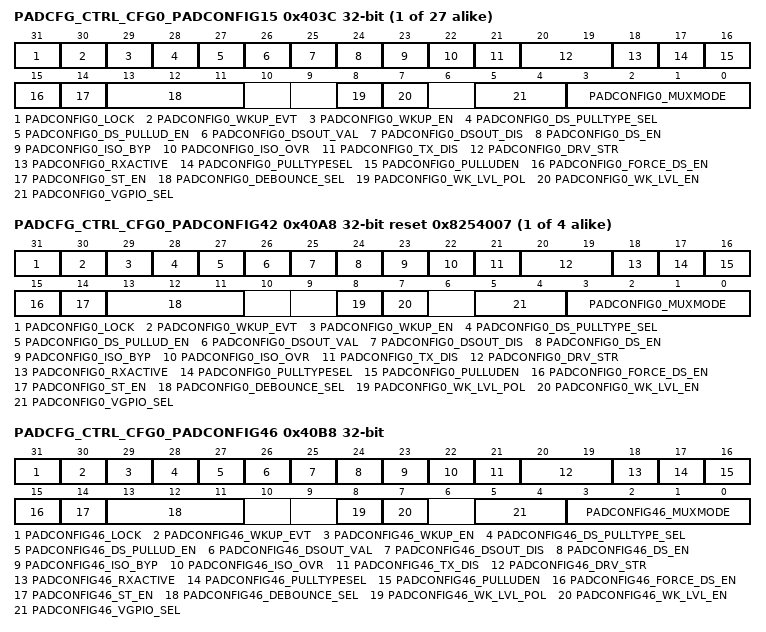
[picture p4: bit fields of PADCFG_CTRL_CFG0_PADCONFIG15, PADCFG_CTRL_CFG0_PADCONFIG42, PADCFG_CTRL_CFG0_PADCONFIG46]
{0x4000+4i} PADCFG_CTRL_CFG0_PADCONFIG{i} (i=15..41) — Register to control pin configuration and muxing
  fields as PADCFG_CTRL_CFG0_PADCONFIG0
{0x4000+4i} PADCFG_CTRL_CFG0_PADCONFIG{i} reset 0x8254007 (i=42..45) — Register to control pin configuration and muxing
  fields as PADCFG_CTRL_CFG0_PADCONFIG0
0x40B8 PADCFG_CTRL_CFG0_PADCONFIG46 — Register to control pin configuration and muxing
  [31] PADCONFIG46_LOCK rw — Lock 0 - Padconfig register is unlocked 1 - Padconfig register is locked from further writes Reset Source: mod_por_rst_n
  [30] PADCONFIG46_WKUP_EVT ro — Wakeup event status 0 - No wake event on pin 1 - Wake event occurred on pin Reset Source: mod_por_rst_n
  [29] PADCONFIG46_WKUP_EN rw — Wakeup enable 0 - Wakeup operation disabled 1 - Wakeup operation enabled Reset Source: mod_por_rst_n
  [28] PADCONFIG46_DS_PULLTYPE_SEL rw — Deep Sleep pull-up/down selection 0 - Offmode pulldown selected 1 - Offmode pullup selected Reset Source: mod_por_rst_n
  [27] PADCONFIG46_DS_PULLUD_EN rw — Deep Sleep pull-up/down enable (active low) 0 - Pullup / pulldown is enabled 1 - Pullup / pulldown is disabled Reset Source: mod_por_rst_n
  [26] PADCONFIG46_DSOUT_VAL rw — Deep Sleep output value 0 - Output value is 0 1 - Output value is 1 Reset Source: mod_por_rst_n
  [25] PADCONFIG46_DSOUT_DIS rw — Deep Sleep output disable 0 - Output enabled 1 - Output disabled Reset Source: mod_por_rst_n
  [24] PADCONFIG46_DS_EN rw — Deep Sleep override control 0 - IO keeps its previous state when Deep Sleep mode is active 1 - IO state is forced to OFF mode value when Deep Sleep mode is active Reset Source: mod_por_rst_n
  [23] PADCONFIG46_ISO_BYP rw — Isolation Bypass0 - IO isolation is preserved1 - IO isolation is bypassed Reset Source: mod_por_rst_n
  [22] PADCONFIG46_ISO_OVR rw — Isolation Override0 - IO isolation is preserved1 - IO isolation is overridden Reset Source: mod_por_rst_n
  [21] PADCONFIG46_TX_DIS rw — Driver Disable0 - Driver is enabled1 - Driver is disabled Reset Source: mod_por_rst_n
  [20:19] PADCONFIG46_DRV_STR rw — Drive Strength Control for dual volatge IOs. Selects the drive strength value for LVCMOS pins. For 1.8V only IO, bitundefined maps to Slew Control pin. Reset Source: mod_por_rst_n
  [18] PADCONFIG46_RXACTIVE rw — Input enable for the Pad0 - Receiver disabled1 - Receiver enabled Reset Source: mod_por_rst_n
  [17] PADCONFIG46_PULLTYPESEL rw — Pad Pullup / Pulldown type selection0 - Pulldown selected1 - Pullup selected Reset Source: mod_por_rst_n
  [16] PADCONFIG46_PULLUDEN rw — Pad Pullup / Pulldown enable. This is an active low signal.0 - Pullup / Pulldown enabled1 - Pullup / Pulldown disabled Reset Source: mod_por_rst_n
  [15] PADCONFIG46_FORCE_DS_EN rw — Enable pad Deep Sleep controls by overriding WKUP DM gating0 - Deep Sleep pad controls are gated by the WKUP DM1 - Activate Deep Sleep pad controls (override WKUP DM gating logic) Reset Source: mod_por_rst_n
  [14] PADCONFIG46_ST_EN rw — Receiver Schmitt Trigger enable 0 - Schmitt trigger input disabled 1 - Schmitt trigger input enabled Reset Source: mod_por_rst_n
  [13:11] PADCONFIG46_DEBOUNCE_SEL rw — Selects the debouce period for the pad. Reset Source: mod_por_rst_n
  [8] PADCONFIG46_WK_LVL_POL rw — Level Sensitive Wakeup PolarityThis bit is not relevant unless wk_lvl_en is set to 1'b1.0 - Low. A low (0) value on the pin causes a wakeup1 - High. A high (1) value on the pin causes a wakeup Reset Source: mod_por_rst_n
  [7] PADCONFIG46_WK_LVL_EN rw — Level Sensitive Wakeup Enable0 - Disabled. Wakeup is triggered by change of the pin input value1 - Enabled. Wakeup is triggered when the pin matches the value specified by wk_lvl_pol. The chosen polarity must be maintained. (e.g. until wakeup completion is confirmed) Reset Source: mod_por_rst_n
  [5:4] PADCONFIG46_VGPIO_SEL rw — Virtual MAIN_GPIO instance select.These bits select which instance of GPIO is used for this I/O pad. This allows protection between two different Processor virtual worlds. These bits have no effect if GPIO mode (muxmode=7) is not selected for the PAD. Refer Pinmux to identify if a pin supports virtual GPIO function or not.Field values (others are reserved):2'b00 - Implement GPIO in GPIO_0 instance2'b01 - Implement GPIO in GPIO_2 instance Reset Source: mod_por_rst_n
  [3:0] PADCONFIG46_MUXMODE rw — Pad functional signal mux selectionField values (others are reserved):4'b0000 - Mux Mode 04'b0001 - Mux Mode 14'b0010 - Mux Mode 24'b0011 - Mux Mode 34'b0100 - Mux Mode 44'b0101 - Mux Mode 54'b0110 - Mux Mode 64'b0111 - Mux Mode 74'b1000 - Mux Mode 84'b1001 - Mux Mode 94'b1010 - Mux Mode 104'b1011 - Mux Mode 114'b1100 - Mux Mode 124'b1101 - Mux Mode 134'b1110 - Mux Mode 144'b1111 - Mux Mode 15 Reset Source: mod_por_rst_n
